# TLE984x register map
Vendor: Infineon Technologies AG; File version: 1.6
SVD file
CPU: CM0 r0p0, little endian, no MPU, no FPU, 2 interrupt priority bits
Registers are 32-bit, read-write, no defined reset value unless marked. A register's access mark holds for its fields unless they carry their own. Offsets are from the block's base; lines under a group give offsets from that group; [hi:lo] are bit positions; {n}, {i} and the like mark numbered series; 'fields as' and 'values as' point back to an identical list; <NAME> marks a mode.

## Memory map
0x40004000 ADC1 size 0x4000
0x4000C000 CCU6 size 0x4000
0x40010000 GPT12E size 0x4000
0x4001C000 LS size 0x4000
0x40024000 HS size 0x4000
0x48004000 TIMER2 size 0x1000
0x48005000 TIMER21 size 0x1000
0x48018000 MF size 0x4000
0x4801C000 ADC2 size 0x2000
0x4801E000 LIN size 0x2000
0x48020000 UART1 size 0x2000
0x48022000 UART2 size 0x2000
0x48024000 SSC1 size 0x2000
0x48026000 SSC2 size 0x2000
0x48028000 PORT size 0x2000
0x50004000 PMU size 0x1000
0x50005000 SCU size 0x1000
0x50006000 SCUPM size 0x1000
0xE000E000 CPU size 0x1000

## LIN
Base 0x4801E000
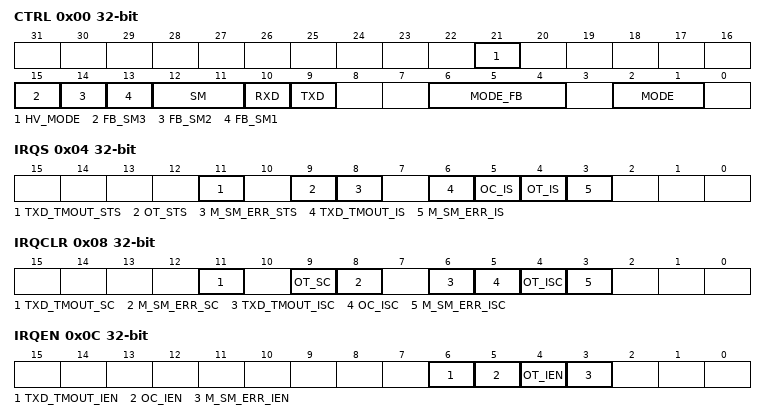
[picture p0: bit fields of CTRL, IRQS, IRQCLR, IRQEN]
0x00 CTRL access per field — LIN Transceiver Control
  [21] HV_MODE rw — LIN Transceiver High Voltage Input - Output Mode
    0=DISABLE (High Voltage Mode Entry is disabled); 1=ENABLE (High Voltage Mode Entry is enabled)
  [15] FB_SM3 ro — Feedback Signal 3 for Slope Mode Setting
  [14] FB_SM2 ro — Feedback Signal 2 for Slope Mode Setting
  [13] FB_SM1 ro — Feedback Signal 1 for Slope Mode Setting
  [12:11] SM rw — LIN Transmitter Slope mode control
    0=Normal Slope Mode (for max. 20 kBaud); 1=Fast Slope Mode (for max. 40 kBaud); 2=Low Slope Mode (for max. 10.4 kBaud); 3=Flash Mode (for max. 150 kBaud#)
  [10] RXD ro — Output Signal of Receiver
  [9] TXD rw — LIN Transmitter switch on (only used when LIN_HV_MODE is set)
    0=Pull Down LIN Line (Transmitter is switched on); 1=Pull Up Resistor is active (Transmitter is switched off)
  [6:4] MODE_FB ro — Feedback Signals for LIN Transmitter Mode Settings
  [2:1] MODE rw — LIN transceiver power mode control
    0=LIN Sleep Mode (LIN module switched to LIN Sleep Mode); 1=LIN Receive-Only Mode (LIN module switched to LIN Receive Only Mode); 3=LIN Normal Mode (LIN module switched to LIN Normal Mode)
0x04 IRQS ro — LIN Transceiver Interrupt Status
  [11] TXD_TMOUT_STS — LIN TXD time-out Status
    0=NO_TIMEOUT (no time-out occurred); 1=TIMEOUT (time-out occurred)
  [9] OT_STS — LIN Receiver Overtemperature Status
    0=no Overtemperature (overtemperature occurred); 1=overtemperature occurred
  [8] M_SM_ERR_STS — LIN Transceiver Mode Error - Slope Mode Error Status
    0=no Mode Error - Slope Mode (status occurred); 1=Mode Error (status occurred)
  [6] TXD_TMOUT_IS — LIN TXD time-out Interrupt Status
    values as TXD_TMOUT_STS
  [5] OC_IS — LIN Receiver Overcurrent Interrupt Status
    0=no Overcurrent (overcurrent status occurred); 1=overcurrent status occurred
  [4] OT_IS — LIN Receiver Overtemperature Interrupt Status
    values as OT_STS
  [3] M_SM_ERR_IS — LIN Transceiver Mode Error - Slope Mode Error Interrupt Status
    values as M_SM_ERR_STS
0x08 IRQCLR wo — LIN Transceiver Interrupt Status Register Clear
  [11] TXD_TMOUT_SC — LIN TXD time-out Status Clear
    0=NO_Clear (no time-out cleared); 1=Clear (time-out cleared)
  [9] OT_SC — LIN Receiver Overtemperature Status Clear
    0=NO_Clear (overtemperature not cleared); 1=Clear (overtemperature cleared)
  [8] M_SM_ERR_SC — LIN Transceiver Mode Error - Slope Mode Error Status Clear
    values as OT_SC
  [6] TXD_TMOUT_ISC — LIN TXD time-out Interrupt Status Clear
    0=NO_Clear (no time-out cleared); 1=Clear (time-out cleared)
  [5] OC_ISC — LIN Receiver Overcurrent Interrupt Status Clear
    0=NO_Clear (overcurrent status not cleared); 1=Clear (overcurrent status cleared)
  [4] OT_ISC — LIN Receiver Overtemperature Interrupt Status / Status Clear
    values as OT_SC
  [3] M_SM_ERR_ISC — LIN Transceiver Mode Error - Slope Mode Error Interrupt Status Clear
    values as OT_SC
0x0C IRQEN — LIN Transceiver Interrupt Enable Register
  [all] fields
    0=disable; 1=enable
  [6] TXD_TMOUT_IEN — LIN Transceiver TxD-Timeout interrupt enable
  [5] OC_IEN — LIN Transceiver Overcurrent interrupt enable
  [4] OT_IEN — LIN Transceiver Overtemperature interrupt enable
  [3] M_SM_ERR_IEN — LIN Transceiver Mode - Slope Mode Error interrupt enable
